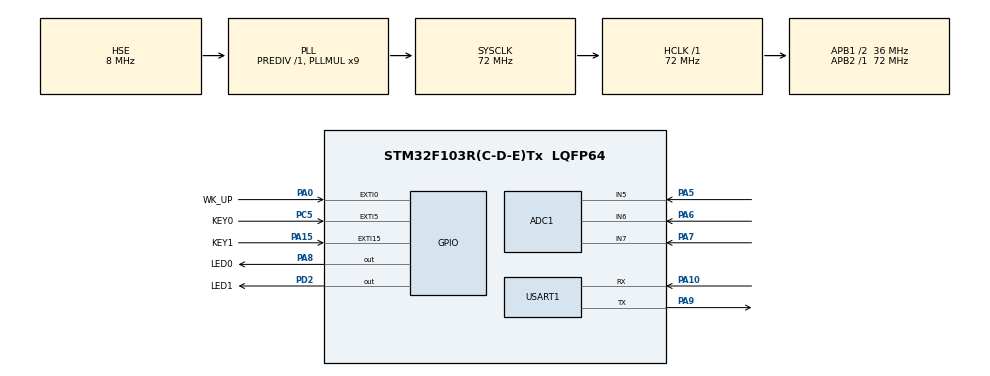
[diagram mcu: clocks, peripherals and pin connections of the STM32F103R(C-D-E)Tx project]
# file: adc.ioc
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ADC1.Channel-1\#ChannelRegularConversion=ADC_CHANNEL_7
ADC1.Channel-2\#ChannelRegularConversion=ADC_CHANNEL_5
ADC1.Channel-3\#ChannelRegularConversion=ADC_CHANNEL_6
ADC1.ContinuousConvMode=DISABLE
ADC1.DiscontinuousConvMode=ENABLE
ADC1.NbrOfConversion=3
ADC1.NbrOfConversionFlag=1
ADC1.Rank-1\#ChannelRegularConversion=1
ADC1.Rank-2\#ChannelRegularConversion=2
ADC1.Rank-3\#ChannelRegularConversion=3
ADC1.SamplingTime-1\#ChannelRegularConversion=ADC_SAMPLETIME_1CYCLE_5
ADC1.SamplingTime-2\#ChannelRegularConversion=ADC_SAMPLETIME_1CYCLE_5
ADC1.SamplingTime-3\#ChannelRegularConversion=ADC_SAMPLETIME_1CYCLE_5
ADC1.master=1
Mcu.Family=STM32F1
Mcu.Name=STM32F103R(C-D-E)Tx
Mcu.Package=LQFP64
NVIC.EXTI0_IRQn=true\:1\:0\:true\:false\:true\:true\:true\:true
NVIC.EXTI15_10_IRQn=true\:1\:2\:true\:false\:true\:true\:true\:true
NVIC.EXTI9_5_IRQn=true\:1\:1\:true\:false\:true\:true\:true\:true
NVIC.PriorityGroup=NVIC_PRIORITYGROUP_2
NVIC.USART1_IRQn=true\:1\:3\:true\:false\:true\:true\:true\:true
PA0-WKUP.GPIO_Label=WK_UP
PA0-WKUP.GPIO_PuPd=GPIO_PULLDOWN
PA0-WKUP.Signal=GPXTI0
PA10.Mode=Asynchronous
PA10.Signal=USART1_RX
PA13.Mode=Serial_Wire
PA13.Signal=SYS_JTMS-SWDIO
PA14.Mode=Serial_Wire
PA14.Signal=SYS_JTCK-SWCLK
PA15.GPIO_Label=KEY1
PA15.GPIO_ModeDefaultEXTI=GPIO_MODE_IT_FALLING
PA15.GPIO_PuPd=GPIO_PULLUP
PA15.Signal=GPXTI15
PA5.Signal=ADCx_IN5
PA6.Signal=ADCx_IN6
PA7.Signal=ADCx_IN7
PA8.GPIO_Label=LED0
PA8.PinState=GPIO_PIN_SET
PA8.Signal=GPIO_Output
PA9.Mode=Asynchronous
PA9.Signal=USART1_TX
PC5.GPIO_Label=KEY0
PC5.GPIO_ModeDefaultEXTI=GPIO_MODE_IT_FALLING
PC5.GPIO_PuPd=GPIO_PULLUP
PC5.Signal=GPXTI5
PD0-OSC_IN.Mode=HSE-External-Oscillator
PD0-OSC_IN.Signal=RCC_OSC_IN
PD1-OSC_OUT.Mode=HSE-External-Oscillator
PD1-OSC_OUT.Signal=RCC_OSC_OUT
PD2.GPIO_Label=LED1
PD2.PinState=GPIO_PIN_SET
PD2.Signal=GPIO_Output
ProjectManager.HeapSize=0x200
ProjectManager.StackSize=0x400
ProjectManager.TargetToolchain=STM32CubeIDE
RCC.ADCPresc=RCC_ADCPCLK2_DIV6
RCC.AHBFreq_Value=72000000
RCC.APB1CLKDivider=RCC_HCLK_DIV2
RCC.APB1Freq_Value=36000000
RCC.APB1TimFreq_Value=72000000
RCC.APB2Freq_Value=72000000
RCC.APB2TimFreq_Value=72000000
RCC.HCLKFreq_Value=72000000
RCC.PLLMUL=RCC_PLL_MUL9
RCC.PLLSourceVirtual=RCC_PLLSOURCE_HSE
RCC.SYSCLKFreq_VALUE=72000000
RCC.SYSCLKSource=RCC_SYSCLKSOURCE_PLLCLK
RCC.USBFreq_Value=72000000
SH.ADCx_IN5.0=ADC1_IN5,IN5
SH.ADCx_IN6.0=ADC1_IN6,IN6
SH.ADCx_IN7.0=ADC1_IN7,IN7
USART1.VirtualMode=VM_ASYNC
board=custom

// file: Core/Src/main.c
/* USER CODE BEGIN Header */
/**
  ******************************************************************************
  * @file           : main.c
  * @brief          : Main program body
  ******************************************************************************
  * @attention
  *
  * <h2><center>&copy; Copyright (c) 2024 STMicroelectronics.
  * All rights reserved.</center></h2>
  *
  * This software component is licensed by ST under BSD 3-Clause license,
  * the "License"; You may not use this file except in compliance with the
  * License. You may obtain a copy of the License at:
  *                        opensource.org/licenses/BSD-3-Clause
  *
  ******************************************************************************
  */
/* USER CODE END Header */
#include "main.h"
#include "adc.h"
#include "usart.h"
#include "gpio.h"

/* USER CODE BEGIN Includes */
#include "lcd.h"
/* USER CODE END Includes */

void SystemClock_Config(void);

int main(void)
{

  /* MCU Configuration--------------------------------------------------------*/

  /* Reset of all peripherals, Initializes the Flash interface and the Systick. */
  HAL_Init();

  /* Configure the system clock */
  SystemClock_Config();

  /* Initialize all configured peripherals */
  MX_GPIO_Init();
  MX_USART1_UART_Init();
  MX_ADC1_Init();
  /* USER CODE BEGIN 2 */
  lcd_init();
  uint16_t raw;
  char msg[20];
  double vol;
  // HAL_UART_Transmit(&huart1, "Start\r\n", 7, HAL_MAX_DELAY);
  HAL_ADC_Start(&hadc1);
  /* USER CODE END 2 */

  /* Infinite loop */
  /* USER CODE BEGIN WHILE */
  while (1)
  {
	  for (int i = 5; i < 8; i++)
	  {
		  HAL_ADC_Start(&hadc1);
		  HAL_ADC_PollForConversion(&hadc1, HAL_MAX_DELAY);
		  raw = HAL_ADC_GetValue(&hadc1);
		  vol = (double) raw * (3.3 / 4096); // the voltage should be raw * (3.3/4096)(12 bits)
		  sprintf(msg, "ch:%d voltage = %f", i, vol);
		  lcd_show_string(30, 50 + 20 * (i - 5), 200, 16, 16, msg, BLACK);
	  }
	  HAL_Delay(200);
    /* USER CODE END WHILE */

  }
}

void SystemClock_Config(void)
{
  RCC_OscInitTypeDef RCC_OscInitStruct = {0};
  RCC_ClkInitTypeDef RCC_ClkInitStruct = {0};
  RCC_PeriphCLKInitTypeDef PeriphClkInit = {0};

  /** Initializes the RCC Oscillators according to the specified parameters
  * in the RCC_OscInitTypeDef structure.
  */
  RCC_OscInitStruct.OscillatorType = RCC_OSCILLATORTYPE_HSE;
  RCC_OscInitStruct.HSEState = RCC_HSE_ON;
  RCC_OscInitStruct.HSEPredivValue = RCC_HSE_PREDIV_DIV1;
  RCC_OscInitStruct.HSIState = RCC_HSI_ON;
  RCC_OscInitStruct.PLL.PLLState = RCC_PLL_ON;
  RCC_OscInitStruct.PLL.PLLSource = RCC_PLLSOURCE_HSE;
  RCC_OscInitStruct.PLL.PLLMUL = RCC_PLL_MUL9;
  if (HAL_RCC_OscConfig(&RCC_OscInitStruct) != HAL_OK)
  {
    Error_Handler();
  }
  /** Initializes the CPU, AHB and APB buses clocks
  */
  RCC_ClkInitStruct.ClockType = RCC_CLOCKTYPE_HCLK|RCC_CLOCKTYPE_SYSCLK
                              |RCC_CLOCKTYPE_PCLK1|RCC_CLOCKTYPE_PCLK2;
  RCC_ClkInitStruct.SYSCLKSource = RCC_SYSCLKSOURCE_PLLCLK;
  RCC_ClkInitStruct.AHBCLKDivider = RCC_SYSCLK_DIV1;
  RCC_ClkInitStruct.APB1CLKDivider = RCC_HCLK_DIV2;
  RCC_ClkInitStruct.APB2CLKDivider = RCC_HCLK_DIV1;

  if (HAL_RCC_ClockConfig(&RCC_ClkInitStruct, FLASH_LATENCY_2) != HAL_OK)
  {
    Error_Handler();
  }
  PeriphClkInit.PeriphClockSelection = RCC_PERIPHCLK_ADC;
  PeriphClkInit.AdcClockSelection = RCC_ADCPCLK2_DIV6;
  if (HAL_RCCEx_PeriphCLKConfig(&PeriphClkInit) != HAL_OK)
  {
    Error_Handler();
  }
}

void Error_Handler(void)
{
  __disable_irq();
  while (1)
  {
  }
}

/************************ (C) COPYRIGHT STMicroelectronics *****END OF FILE****/
